# HDSC_HC32F4A0 register map
Vendor: HDSC Co.,Ltd.; Series: ARMCM4; File version: 1.0
CPU: CM4 r0p1, little endian, MPU, FPU, 4 interrupt priority bits
Registers are 32-bit, read-write, reset 0x0 unless marked. A register's access mark holds for its fields unless they carry their own. Offsets are from the block's base; [hi:lo] are bit positions; {n}, {i} and the like mark numbered series.

## DMA1
Base 0x40053000
Same registers: DMA2 0x40053400
0x00 EN
  [0] EN
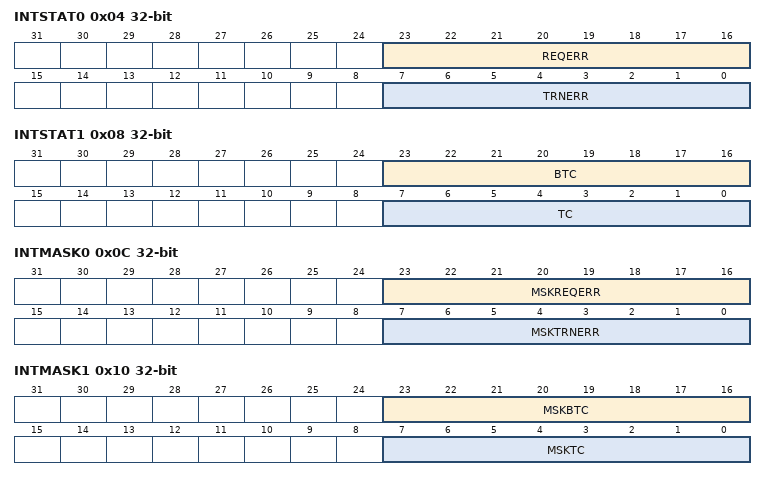
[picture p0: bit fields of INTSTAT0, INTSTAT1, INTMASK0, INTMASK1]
0x04 INTSTAT0 ro
  [23:16] REQERR, [7:0] TRNERR
0x08 INTSTAT1 ro
  [23:16] BTC, [7:0] TC
0x0C INTMASK0
  [23:16] MSKREQERR, [7:0] MSKTRNERR
0x10 INTMASK1
  [23:16] MSKBTC, [7:0] MSKTC
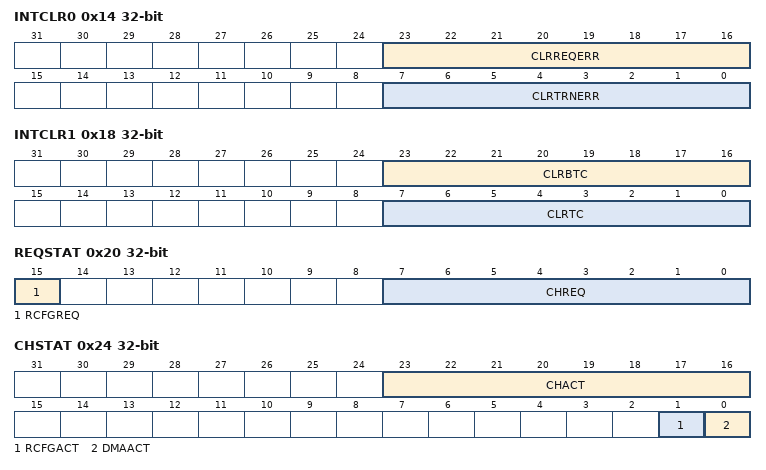
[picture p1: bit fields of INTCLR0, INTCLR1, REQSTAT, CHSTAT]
0x14 INTCLR0 wo
  [23:16] CLRREQERR, [7:0] CLRTRNERR
0x18 INTCLR1 wo
  [23:16] CLRBTC, [7:0] CLRTC
0x1C CHEN
  [7:0] CHEN
0x20 REQSTAT ro
  [15] RCFGREQ, [7:0] CHREQ
0x24 CHSTAT ro
  [23:16] CHACT, [1] RCFGACT, [0] DMAACT
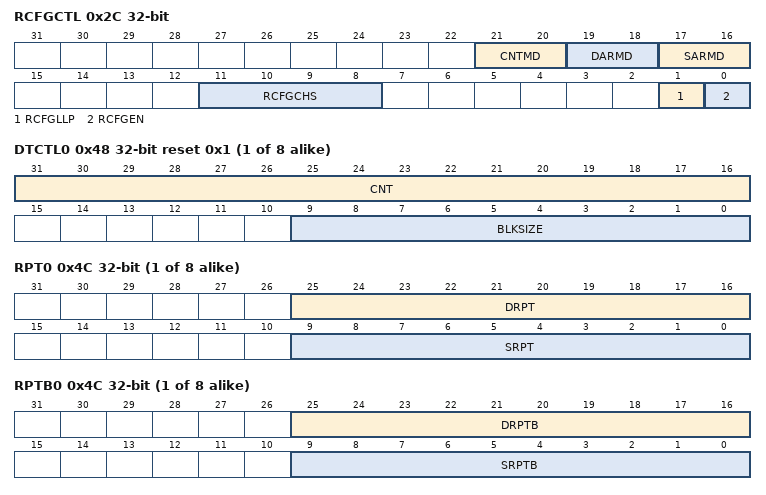
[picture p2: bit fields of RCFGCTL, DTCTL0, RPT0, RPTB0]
0x2C RCFGCTL
  [21:20] CNTMD, [19:18] DARMD, [17:16] SARMD, [11:8] RCFGCHS, [1] RCFGLLP, [0] RCFGEN
0x34 CHENCLR wo
  [7:0] CHENCLR
{0x40+0x40*i} SAR{i} (i=0..7)
{0x44+0x40*i} DAR{i} (i=0..7)
{0x48+0x40*i} DTCTL{i} reset 0x1 (i=0..7)
  [31:16] CNT, [9:0] BLKSIZE
{0x4C+0x40*i} RPT{i} (i=0..7)
  [25:16] DRPT, [9:0] SRPT
{0x4C+0x40*i} RPTB{i} (i=0..7)
  [25:16] DRPTB, [9:0] SRPTB
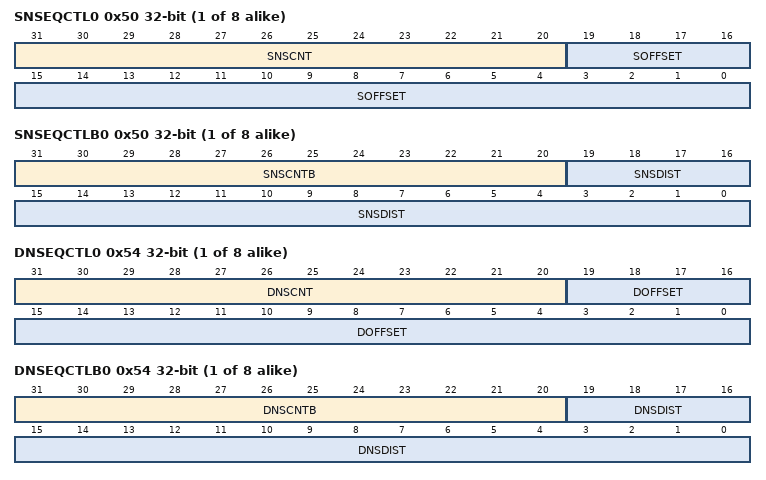
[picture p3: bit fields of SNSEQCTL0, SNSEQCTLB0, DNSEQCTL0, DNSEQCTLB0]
{0x50+0x40*i} SNSEQCTL{i} (i=0..7)
  [31:20] SNSCNT, [19:0] SOFFSET
{0x50+0x40*i} SNSEQCTLB{i} (i=0..7)
  [31:20] SNSCNTB, [19:0] SNSDIST
{0x54+0x40*i} DNSEQCTL{i} (i=0..7)
  [31:20] DNSCNT, [19:0] DOFFSET
{0x54+0x40*i} DNSEQCTLB{i} (i=0..7)
  [31:20] DNSCNTB, [19:0] DNSDIST
{0x58+0x40*i} LLP{i} (i=0..7)
  [31:2] LLP
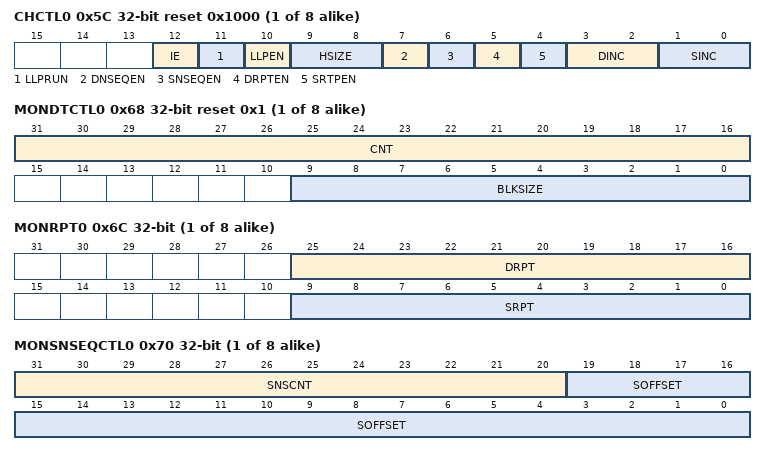
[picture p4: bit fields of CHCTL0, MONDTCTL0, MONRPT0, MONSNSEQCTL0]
{0x5C+0x40*i} CHCTL{i} reset 0x1000 (i=0..7)
  [12] IE, [11] LLPRUN, [10] LLPEN, [9:8] HSIZE, [7] DNSEQEN, [6] SNSEQEN, [5] DRPTEN, [4] SRTPEN, [3:2] DINC, [1:0] SINC
{0x60+0x40*i} MONSAR{i} ro (i=0..7)
{0x64+0x40*i} MONDAR{i} ro (i=0..7)
{0x68+0x40*i} MONDTCTL{i} ro reset 0x1 (i=0..7)
  [31:16] CNT, [9:0] BLKSIZE
{0x6C+0x40*i} MONRPT{i} ro (i=0..7)
  [25:16] DRPT, [9:0] SRPT
{0x70+0x40*i} MONSNSEQCTL{i} ro (i=0..7)
  [31:20] SNSCNT, [19:0] SOFFSET
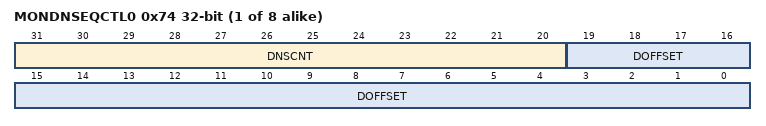
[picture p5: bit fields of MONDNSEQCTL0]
{0x74+0x40*i} MONDNSEQCTL{i} ro (i=0..7)
  [31:20] DNSCNT, [19:0] DOFFSET

## DMC
Base 0x88000400
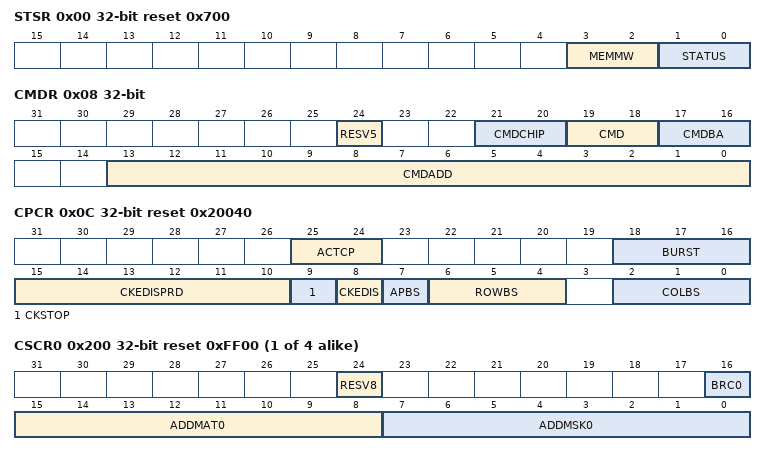
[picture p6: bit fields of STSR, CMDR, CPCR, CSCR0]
0x00 STSR ro reset 0x700
  [3:2] MEMMW, [1:0] STATUS
0x04 STCR wo
  [2:0] STCTL
0x08 CMDR wo
  [24] RESV5 rw, [21:20] CMDCHIP, [19:18] CMD, [17:16] CMDBA, [13:0] CMDADD
0x0C CPCR reset 0x20040
  [25:24] ACTCP, [18:16] BURST, [15:10] CKEDISPRD, [9] CKSTOP, [8] CKEDIS, [7] APBS, [6:4] ROWBS, [2:0] COLBS
0x10 RFTR reset 0xA60
  [14:0] REFPRD
0x14 TMCR_T_CASL reset 0x3
  [2:0] T_CASL
0x18 TMCR_T_DQSS reset 0x1
  [1:0] T_DQSS
0x1C TMCR_T_MRD reset 0x2
  [6:0] T_MRD
0x20 TMCR_T_RAS reset 0x7
  [3:0] T_RAS
0x24 TMCR_T_RC reset 0xB
  [3:0] T_RC
0x28 TMCR_T_RCD reset 0x35
  [2:0] T_RCD
0x2C TMCR_T_RFC reset 0x1012
  [4:0] T_RFC
0x30 TMCR_T_RP reset 0x35
  [2:0] T_RP
0x34 TMCR_T_RRD reset 0x2
  [3:0] T_RRD
0x38 TMCR_T_WR reset 0x3
  [2:0] T_WR
0x3C TMCR_T_WTR reset 0x2
  [2:0] T_WTR
0x40 TMCR_T_XP reset 0x1
  [7:0] T_XP
0x44 TMCR_T_XSR reset 0xA
  [7:0] T_XSR
0x48 TMCR_T_ESR reset 0x14
  [7:0] T_ESR
{0x200+4i} CSCR{i} reset 0xFF00 (i=0..3)
  [24] RESV{i+8}, [16] BRC{i}, [15:8] ADDMAT{i}, [7:0] ADDMSK{i}
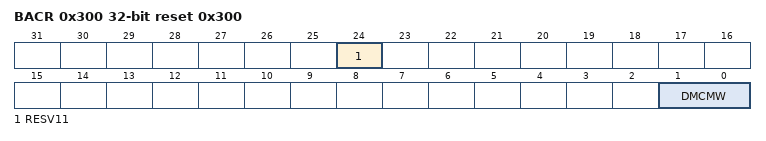
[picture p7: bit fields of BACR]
0x300 BACR reset 0x300
  [24] RESV11, [1:0] DMCMW

## DVP
Base 0x40055800
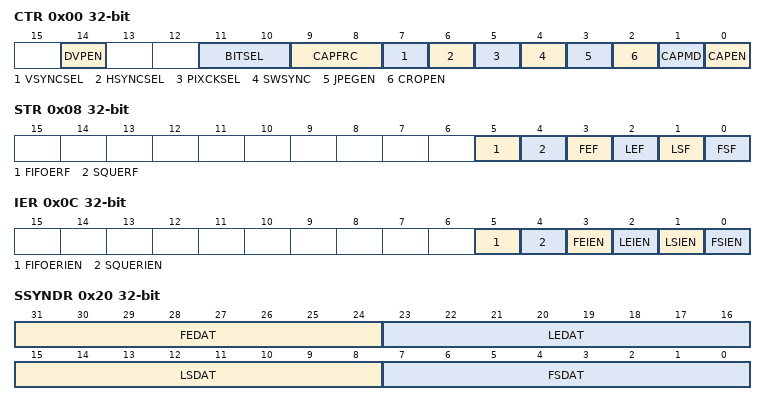
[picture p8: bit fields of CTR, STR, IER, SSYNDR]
0x00 CTR
  [14] DVPEN, [11:10] BITSEL, [9:8] CAPFRC, [7] VSYNCSEL, [6] HSYNCSEL, [5] PIXCKSEL, [4] SWSYNC, [3] JPEGEN, [2] CROPEN, [1] CAPMD, [0] CAPEN
0x04 DTR reset 0x10
0x08 STR
  [5] FIFOERF, [4] SQUERF, [3] FEF, [2] LEF, [1] LSF, [0] FSF
0x0C IER
  [5] FIFOERIEN, [4] SQUERIEN, [3] FEIEN, [2] LEIEN, [1] LSIEN, [0] FSIEN
0x10 DMR
0x20 SSYNDR
  [31:24] FEDAT, [23:16] LEDAT, [15:8] LSDAT, [7:0] FSDAT
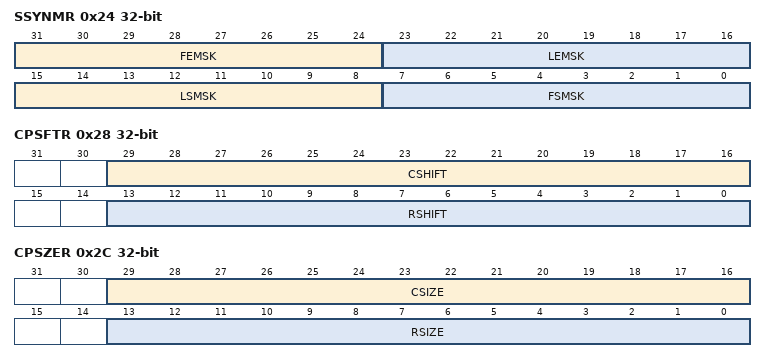
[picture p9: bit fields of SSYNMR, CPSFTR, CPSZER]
0x24 SSYNMR
  [31:24] FEMSK, [23:16] LEMSK, [15:8] LSMSK, [7:0] FSMSK
0x28 CPSFTR
  [29:16] CSHIFT, [13:0] RSHIFT
0x2C CPSZER
  [29:16] CSIZE, [13:0] RSIZE

## EFM
Base 0x40010400
0x00 FAPRT
  [15:0] FAPRT
0x04 KEY1
0x08 KEY2
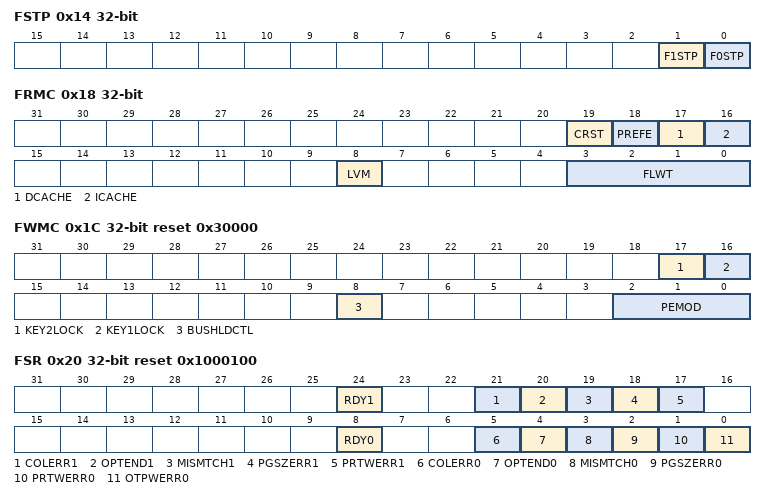
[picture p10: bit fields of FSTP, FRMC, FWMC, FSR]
0x14 FSTP
  [1] F1STP, [0] F0STP
0x18 FRMC
  [19] CRST, [18] PREFE, [17] DCACHE, [16] ICACHE, [8] LVM, [3:0] FLWT
0x1C FWMC reset 0x30000
  [17] KEY2LOCK, [16] KEY1LOCK, [8] BUSHLDCTL, [2:0] PEMOD
0x20 FSR ro reset 0x1000100
  [24] RDY1, [21] COLERR1, [20] OPTEND1, [19] MISMTCH1, [18] PGSZERR1, [17] PRTWERR1, [8] RDY0, [5] COLERR0, [4] OPTEND0, [3] MISMTCH0, [2] PGSZERR0, [1] PRTWERR0, [0] OTPWERR0
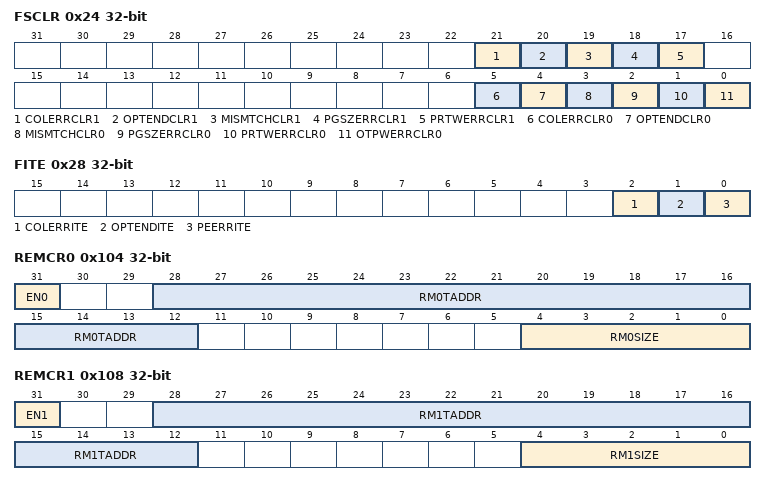
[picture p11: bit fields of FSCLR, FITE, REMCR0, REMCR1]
0x24 FSCLR
  [21] COLERRCLR1, [20] OPTENDCLR1, [19] MISMTCHCLR1, [18] PGSZERRCLR1, [17] PRTWERRCLR1, [5] COLERRCLR0, [4] OPTENDCLR0, [3] MISMTCHCLR0, [2] PGSZERRCLR0, [1] PRTWERRCLR0, [0] OTPWERRCLR0
0x28 FITE
  [2] COLERRITE, [1] OPTENDITE, [0] PEERRITE
0x2C FSWP ro
  [0] FSWP
0x40 FHDFG ro reset 0x484404A0
{0x50+4i} UQID{i} ro (i=0..2)
0x100 REMPRT
  [15:0] REMPRT
0x104 REMCR0
  [31] EN0, [28:12] RM0TADDR, [4:0] RM0SIZE
0x108 REMCR1
  [31] EN1, [28:12] RM1TADDR, [4:0] RM1SIZE
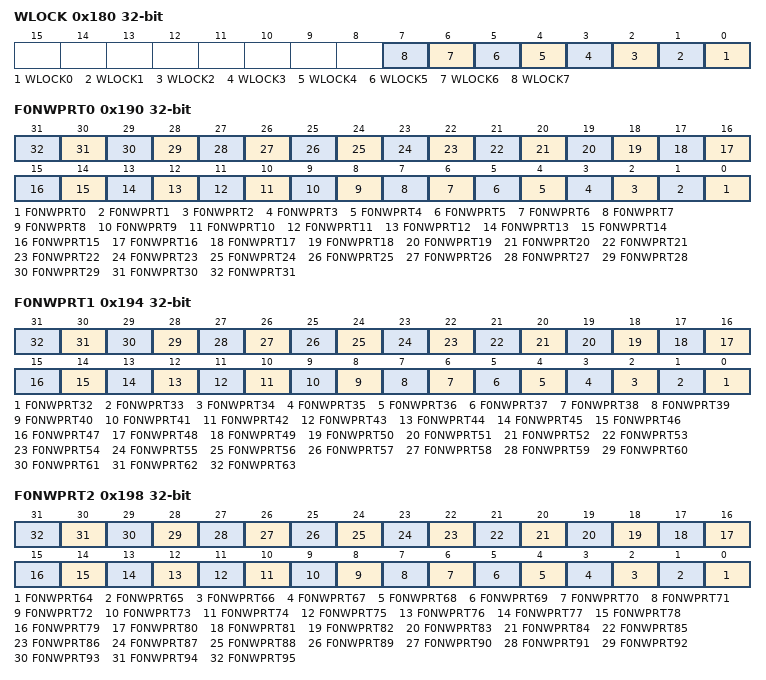
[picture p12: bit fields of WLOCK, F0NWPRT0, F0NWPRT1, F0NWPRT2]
0x180 WLOCK
  [n] WLOCK{n} (n=0..7)
0x190 F0NWPRT0
  [n] F0NWPRT{n} (n=0..31)
0x194 F0NWPRT1
  [n-32] F0NWPRT{n} (n=32..63)
0x198 F0NWPRT2
  [n-64] F0NWPRT{n} (n=64..95)
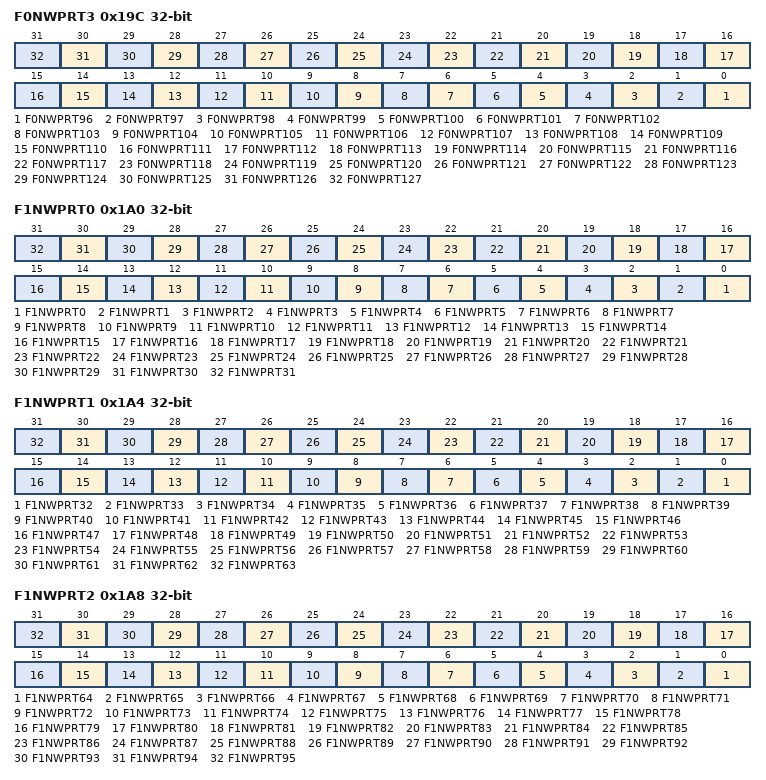
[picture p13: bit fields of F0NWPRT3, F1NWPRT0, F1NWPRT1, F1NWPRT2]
0x19C F0NWPRT3
  [n-96] F0NWPRT{n} (n=96..127)
0x1A0 F1NWPRT0
  [n] F1NWPRT{n} (n=0..31)
0x1A4 F1NWPRT1
  [n-32] F1NWPRT{n} (n=32..63)
0x1A8 F1NWPRT2
  [n-64] F1NWPRT{n} (n=64..95)
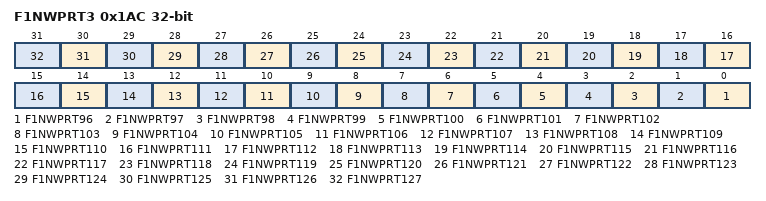
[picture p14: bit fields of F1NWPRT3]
0x1AC F1NWPRT3
  [n-96] F1NWPRT{n} (n=96..127)
